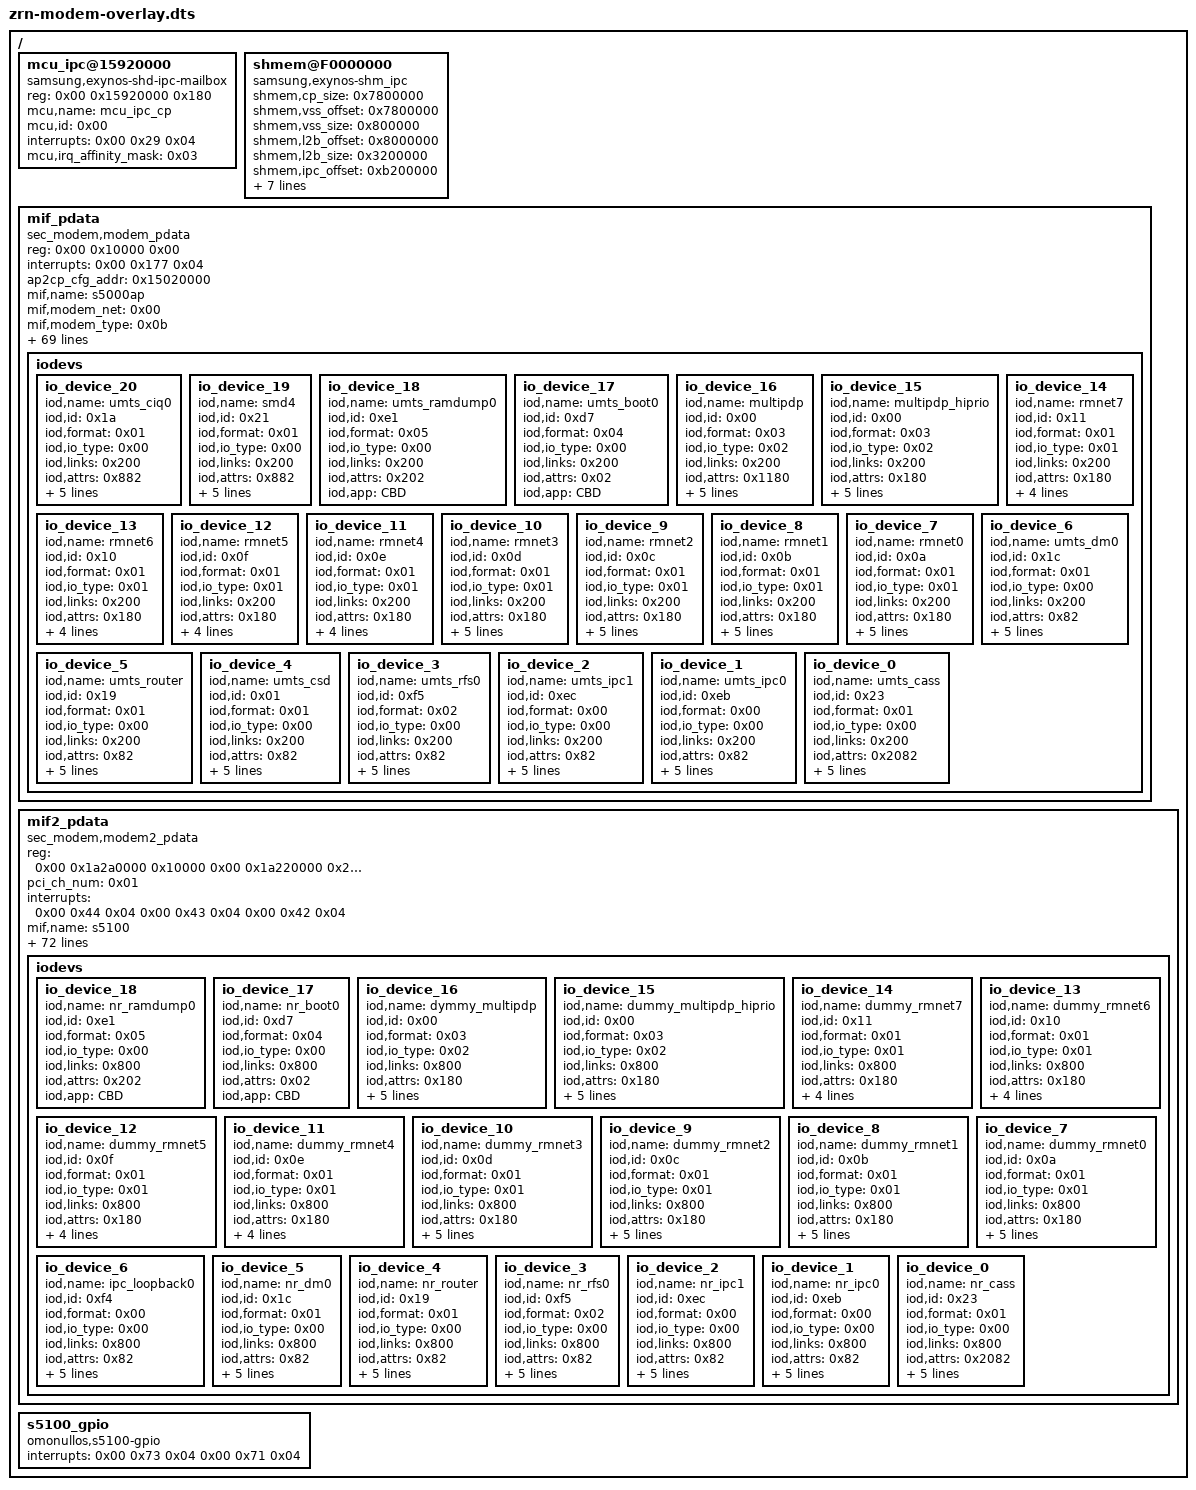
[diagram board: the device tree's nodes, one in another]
/*
 * Generated by modem/beyondx/mkoverlay.py from stock/live/beyondx-twrp-boot.dts:
 * do not edit. See mkoverlay.py for what is dropped and changed.
 */
/dts-v1/;
/plugin/;

/ {
	fragment@0 {
		target-path = "/";
		__overlay__ {
			mcu_ipc@15920000 {
				compatible = "samsung,exynos-shd-ipc-mailbox";
				reg = <0x00 0x15920000 0x180>;
				mcu,name = "mcu_ipc_cp";
				mcu,id = <0x00>;
				interrupts = <0x00 0x29 0x04>;
				mcu,irq_affinity_mask = <0x03>;
			};

			shmem@F0000000 {
				compatible = "samsung,exynos-shm_ipc";
				shmem,cp_size = <0x7800000>;
				shmem,vss_offset = <0x7800000>;
				shmem,vss_size = <0x800000>;
				shmem,l2b_offset = <0x8000000>;
				shmem,l2b_size = <0x3200000>;
				shmem,ipc_offset = <0xb200000>;
				shmem,ipc_size = <0x500000>;
				shmem,zmb_offset = <0x00>;
				shmem,zmb_size = <0x00>;
				shmem,vparam_offset = <0xb700000>;
				shmem,vparam_size = <0x200000>;
				shmem,s5100_ipc_size = <0x800000>;
				shmem,s5100_cp2cp_offset = <0x11600000>;
			};

			mif_pdata {
				reg = <0x00 0x10000 0x00>;
				compatible = "sec_modem,modem_pdata";
				status = "okay";
				interrupts = <0x00 0x177 0x04>;
				ap2cp_cfg_addr = <0x15020000>;
				mif,name = "s5000ap";
				mif,modem_net = <0x00>;
				mif,modem_type = <0x0b>;
				mif,use_handover = <0x00>;
				mif,ipc_version = <0x32>;
				mif,link_types = <0x200>;
				mif,link_name = "shmem";
				mif,link_attrs = <0x7c9>;
				mif,int_ap2cp_msg = <0x00>;
				mif,int_ap2cp_wakeup = <0x01>;
				mif,int_ap2cp_status = <0x02>;
				mif,int_ap2cp_active = <0x03>;
				mif,irq_cp2ap_msg = <0x00>;
				mif,irq_cp2ap_status = <0x02>;
				mif,irq_cp2ap_active = <0x03>;
				mif,irq_cp2ap_perf_req_cpu = <0x05>;
				mif,irq_cp2ap_perf_req_mif = <0x06>;
				mif,irq_cp2ap_perf_req_int = <0x07>;
				mif,irq_cp2ap_wakelock = <0x08>;
				mif,irq_cp2ap_ratmode = <0x09>;
				mif,irq_cp2ap_change_ul_path = <0x0c>;
				mbx_ap2cp_msg = <0x00>;
				mbx_cp2ap_msg = <0x01>;
				mbx_ap2cp_united_status = <0x02>;
				mbx_cp2ap_united_status = <0x03>;
				mbx_cp2ap_dvfsreq_cpu = <0x05>;
				mbx_cp2ap_dvfsreq_mif = <0x06>;
				mbx_cp2ap_dvfsreq_int = <0x07>;
				mbx_ap2cp_kerneltime = <0x09>;
				sbi_nr_crash_type_mask = <0x0f>;
				sbi_nr_crash_type_pos = <0x1b>;
				sbi_crash_type_mask = <0x0f>;
				sbi_crash_type_pos = <0x17>;
				sbi_device_type_mask = <0x1f>;
				sbi_device_type_pos = <0x12>;
				sbi_ext_backtrace_mask = <0x01>;
				sbi_ext_backtrace_pos = <0x11>;
				sbi_ds_det_mask = <0x03>;
				sbi_ds_det_pos = <0x0e>;
				sbi_sys_rev_mask = <0xff>;
				sbi_sys_rev_pos = <0x06>;
				sbi_pda_active_mask = <0x01>;
				sbi_pda_active_pos = <0x05>;
				sbi_ap_status_mask = <0x0f>;
				sbi_ap_status_pos = <0x01>;
				sbi_cp_rat_mode_mask = <0x3f>;
				sbi_cp_rat_mode_pos = <0x1a>;
				sbi_cp_evs_mode_mask = <0x01>;
				sbi_cp_evs_mode_pos = <0x07>;
				sbi_cp2ap_wakelock_mask = <0x01>;
				sbi_cp2ap_wakelock_pos = <0x06>;
				sbi_lte_active_mask = <0x01>;
				sbi_lte_active_pos = <0x05>;
				sbi_cp_status_mask = <0x0f>;
				sbi_cp_status_pos = <0x01>;
				sbi_ap2cp_kerneltime_sec_mask = <0xfff>;
				sbi_ap2cp_kerneltime_sec_pos = <0x14>;
				sbi_ap2cp_kerneltime_usec_mask = <0xfffff>;
				sbi_ap2cp_kerneltime_usec_pos = <0x00>;
				pktproc_support = <0x01>;
				pktproc_version = <0x01>;
				pktproc_cp_base = <0x50000000>;
				pktproc_info_rgn_offset = <0x00>;
				pktproc_info_rgn_size = <0x100>;
				pktproc_desc_rgn_offset = <0x100>;
				pktproc_desc_rgn_size = <0xfff00>;
				pktproc_data_rgn_offset = <0x100000>;
				pktproc_desc_mode = <0x00>;
				pktproc_num_queue = <0x01>;
				pktproc_use_exclusive_irq = <0x00>;
				pktproc_use_hw_iocc = <0x00>;
				mif,num_iodevs = <0x15>;

				iodevs {
					io_device_20 {
						iod,name = "umts_ciq0";
						iod,id = <0x1a>;
						iod,format = <0x01>;
						iod,io_type = <0x00>;
						iod,links = <0x200>;
						iod,attrs = <0x882>;
						iod,ul_num_buffers = <0x10>;
						iod,ul_buffer_size = <0x800>;
						iod,dl_num_buffers = <0x80>;
						iod,dl_buffer_size = <0x800>;
						iod,option_region = "usa_spr";
					};

					io_device_19 {
						iod,name = "smd4";
						iod,id = <0x21>;
						iod,format = <0x01>;
						iod,io_type = <0x00>;
						iod,links = <0x200>;
						iod,attrs = <0x882>;
						iod,ul_num_buffers = <0x10>;
						iod,ul_buffer_size = <0x800>;
						iod,dl_num_buffers = <0x80>;
						iod,dl_buffer_size = <0x800>;
						iod,option_region = "kor_skt";
					};

					io_device_18 {
						iod,name = "umts_ramdump0";
						iod,id = <0xe1>;
						iod,format = <0x05>;
						iod,io_type = <0x00>;
						iod,links = <0x200>;
						iod,attrs = <0x202>;
						iod,app = "CBD";
					};

					io_device_17 {
						iod,name = "umts_boot0";
						iod,id = <0xd7>;
						iod,format = <0x04>;
						iod,io_type = <0x00>;
						iod,links = <0x200>;
						iod,attrs = <0x02>;
						iod,app = "CBD";
					};

					io_device_16 {
						iod,name = "multipdp";
						iod,id = <0x00>;
						iod,format = <0x03>;
						iod,io_type = <0x02>;
						iod,links = <0x200>;
						iod,attrs = <0x1180>;
						iod,app = "RIL";
						iod,ul_num_buffers = <0x200>;
						iod,ul_buffer_size = <0x800>;
						iod,dl_num_buffers = <0x400>;
						iod,dl_buffer_size = <0x08>;
					};

					io_device_15 {
						iod,name = "multipdp_hiprio";
						iod,id = <0x00>;
						iod,format = <0x03>;
						iod,io_type = <0x02>;
						iod,links = <0x200>;
						iod,attrs = <0x180>;
						iod,app = "RIL";
						iod,ul_num_buffers = <0x100>;
						iod,ul_buffer_size = <0x800>;
						iod,dl_num_buffers = <0x100>;
						iod,dl_buffer_size = <0x800>;
					};

					io_device_14 {
						iod,name = "rmnet7";
						iod,id = <0x11>;
						iod,format = <0x01>;
						iod,io_type = <0x01>;
						iod,links = <0x200>;
						iod,attrs = <0x180>;
						iod,ul_num_buffers = <0x00>;
						iod,ul_buffer_size = <0x800>;
						iod,dl_num_buffers = <0x00>;
						iod,dl_buffer_size = <0x800>;
					};

					io_device_13 {
						iod,name = "rmnet6";
						iod,id = <0x10>;
						iod,format = <0x01>;
						iod,io_type = <0x01>;
						iod,links = <0x200>;
						iod,attrs = <0x180>;
						iod,ul_num_buffers = <0x00>;
						iod,ul_buffer_size = <0x800>;
						iod,dl_num_buffers = <0x00>;
						iod,dl_buffer_size = <0x800>;
					};

					io_device_12 {
						iod,name = "rmnet5";
						iod,id = <0x0f>;
						iod,format = <0x01>;
						iod,io_type = <0x01>;
						iod,links = <0x200>;
						iod,attrs = <0x180>;
						iod,ul_num_buffers = <0x00>;
						iod,ul_buffer_size = <0x800>;
						iod,dl_num_buffers = <0x00>;
						iod,dl_buffer_size = <0x800>;
					};

					io_device_11 {
						iod,name = "rmnet4";
						iod,id = <0x0e>;
						iod,format = <0x01>;
						iod,io_type = <0x01>;
						iod,links = <0x200>;
						iod,attrs = <0x180>;
						iod,ul_num_buffers = <0x00>;
						iod,ul_buffer_size = <0x800>;
						iod,dl_num_buffers = <0x00>;
						iod,dl_buffer_size = <0x800>;
					};

					io_device_10 {
						iod,name = "rmnet3";
						iod,id = <0x0d>;
						iod,format = <0x01>;
						iod,io_type = <0x01>;
						iod,links = <0x200>;
						iod,attrs = <0x180>;
						iod,app = "NET";
						iod,ul_num_buffers = <0x00>;
						iod,ul_buffer_size = <0x800>;
						iod,dl_num_buffers = <0x00>;
						iod,dl_buffer_size = <0x800>;
					};

					io_device_9 {
						iod,name = "rmnet2";
						iod,id = <0x0c>;
						iod,format = <0x01>;
						iod,io_type = <0x01>;
						iod,links = <0x200>;
						iod,attrs = <0x180>;
						iod,app = "NET";
						iod,ul_num_buffers = <0x00>;
						iod,ul_buffer_size = <0x800>;
						iod,dl_num_buffers = <0x00>;
						iod,dl_buffer_size = <0x800>;
					};

					io_device_8 {
						iod,name = "rmnet1";
						iod,id = <0x0b>;
						iod,format = <0x01>;
						iod,io_type = <0x01>;
						iod,links = <0x200>;
						iod,attrs = <0x180>;
						iod,app = "NET";
						iod,ul_num_buffers = <0x00>;
						iod,ul_buffer_size = <0x800>;
						iod,dl_num_buffers = <0x00>;
						iod,dl_buffer_size = <0x800>;
					};

					io_device_7 {
						iod,name = "rmnet0";
						iod,id = <0x0a>;
						iod,format = <0x01>;
						iod,io_type = <0x01>;
						iod,links = <0x200>;
						iod,attrs = <0x180>;
						iod,app = "NET";
						iod,ul_num_buffers = <0x00>;
						iod,ul_buffer_size = <0x800>;
						iod,dl_num_buffers = <0x00>;
						iod,dl_buffer_size = <0x800>;
					};

					io_device_6 {
						iod,name = "umts_dm0";
						iod,id = <0x1c>;
						iod,format = <0x01>;
						iod,io_type = <0x00>;
						iod,links = <0x200>;
						iod,attrs = <0x82>;
						iod,app = "DIAG";
						iod,ul_num_buffers = <0x10>;
						iod,ul_buffer_size = <0x800>;
						iod,dl_num_buffers = <0x80>;
						iod,dl_buffer_size = <0x800>;
					};

					io_device_5 {
						iod,name = "umts_router";
						iod,id = <0x19>;
						iod,format = <0x01>;
						iod,io_type = <0x00>;
						iod,links = <0x200>;
						iod,attrs = <0x82>;
						iod,app = "Data Router";
						iod,ul_num_buffers = <0x10>;
						iod,ul_buffer_size = <0x800>;
						iod,dl_num_buffers = <0x10>;
						iod,dl_buffer_size = <0x800>;
					};

					io_device_4 {
						iod,name = "umts_csd";
						iod,id = <0x01>;
						iod,format = <0x01>;
						iod,io_type = <0x00>;
						iod,links = <0x200>;
						iod,attrs = <0x82>;
						iod,app = "CSVT";
						iod,ul_num_buffers = <0x20>;
						iod,ul_buffer_size = <0x800>;
						iod,dl_num_buffers = <0x40>;
						iod,dl_buffer_size = <0x800>;
					};

					io_device_3 {
						iod,name = "umts_rfs0";
						iod,id = <0xf5>;
						iod,format = <0x02>;
						iod,io_type = <0x00>;
						iod,links = <0x200>;
						iod,attrs = <0x82>;
						iod,app = "RFS";
						iod,ul_num_buffers = <0x10>;
						iod,ul_buffer_size = <0x800>;
						iod,dl_num_buffers = <0x200>;
						iod,dl_buffer_size = <0x800>;
					};

					io_device_2 {
						iod,name = "umts_ipc1";
						iod,id = <0xec>;
						iod,format = <0x00>;
						iod,io_type = <0x00>;
						iod,links = <0x200>;
						iod,attrs = <0x82>;
						iod,app = "RIL";
						iod,ul_num_buffers = <0x10>;
						iod,ul_buffer_size = <0x1000>;
						iod,dl_num_buffers = <0x20>;
						iod,dl_buffer_size = <0x1000>;
					};

					io_device_1 {
						iod,name = "umts_ipc0";
						iod,id = <0xeb>;
						iod,format = <0x00>;
						iod,io_type = <0x00>;
						iod,links = <0x200>;
						iod,attrs = <0x82>;
						iod,app = "RIL";
						iod,ul_num_buffers = <0x10>;
						iod,ul_buffer_size = <0x1000>;
						iod,dl_num_buffers = <0x20>;
						iod,dl_buffer_size = <0x1000>;
					};

					io_device_0 {
						iod,name = "umts_cass";
						iod,id = <0x23>;
						iod,format = <0x01>;
						iod,io_type = <0x00>;
						iod,links = <0x200>;
						iod,attrs = <0x2082>;
						iod,max_tx_size = <0x800>;
						iod,ul_num_buffers = <0x10>;
						iod,ul_buffer_size = <0x800>;
						iod,dl_num_buffers = <0x10>;
						iod,dl_buffer_size = <0x800>;
					};
				};
			};

			mif2_pdata {
				reg = <0x00 0x1a2a0000 0x10000 0x00 0x1a220000 0x2000>;
				reg-names = "dit\0sysreg_busc";
				compatible = "sec_modem,modem2_pdata";
				status = "okay";
				pci_ch_num = <0x01>;
				interrupts = <0x00 0x44 0x04 0x00 0x43 0x04 0x00 0x42 0x04>;
				interrupt-names = "DIT_BUS_ERR\0DIT_RX\0DIT_TX";
				mif,name = "s5100";
				mif,modem_net = <0x00>;
				mif,modem_type = <0x0c>;
				mif,use_handover = <0x00>;
				mif,ipc_version = <0x32>;
				mif,link_types = <0x800>;
				mif,link_name = "PCIE";
				mif,link_attrs = <0x7c9>;
				mif,int_ap2cp_msg = <0x00>;
				mif,int_ap2cp_wakeup = <0x01>;
				mif,int_ap2cp_status = <0x02>;
				mif,int_ap2cp_active = <0x03>;
				mif,int_ap2cp_pcie_link_ack = <0x0e>;
				mif,irq_cp2ap_msg = <0x00>;
				mif,irq_cp2ap_status = <0x02>;
				mif,irq_cp2ap_active = <0x03>;
				mif,irq_cp2ap_perf_req_cpu = <0x05>;
				mif,irq_cp2ap_perf_req_mif = <0x06>;
				mif,irq_cp2ap_perf_req_int = <0x07>;
				mif,irq_cp2ap_wakelock = <0x08>;
				mif,irq_cp2ap_ratmode = <0x09>;
				mif,irq_cp2ap_change_ul_path = <0x0c>;
				mbx_ap2cp_msg = <0x00>;
				mbx_cp2ap_msg = <0x01>;
				mbx_ap2cp_united_status = <0x02>;
				mbx_cp2ap_united_status = <0x03>;
				mbx_cp2ap_dvfsreq_cpu = <0x05>;
				mbx_cp2ap_dvfsreq_mif = <0x06>;
				mbx_cp2ap_dvfsreq_int = <0x07>;
				mbx_ap2cp_kerneltime = <0x09>;
				sbi_crash_type_mask = <0x0f>;
				sbi_crash_type_pos = <0x17>;
				sbi_ext_backtrace_mask = <0x01>;
				sbi_ext_backtrace_pos = <0x11>;
				sbi_ds_det_mask = <0x03>;
				sbi_ds_det_pos = <0x0e>;
				sbi_sys_rev_mask = <0xff>;
				sbi_sys_rev_pos = <0x06>;
				sbi_pda_active_mask = <0x01>;
				sbi_pda_active_pos = <0x05>;
				sbi_ap_status_mask = <0x0f>;
				sbi_ap_status_pos = <0x01>;
				sbi_cp_rat_mode_mask = <0x3f>;
				sbi_cp_rat_mode_pos = <0x1a>;
				sbi_cp_evs_mode_mask = <0x01>;
				sbi_cp_evs_mode_pos = <0x07>;
				sbi_cp2ap_wakelock_mask = <0x01>;
				sbi_cp2ap_wakelock_pos = <0x06>;
				sbi_lte_active_mask = <0x01>;
				sbi_lte_active_pos = <0x05>;
				sbi_cp_status_mask = <0x0f>;
				sbi_cp_status_pos = <0x01>;
				sbi_ap2cp_kerneltime_sec_mask = <0xfff>;
				sbi_ap2cp_kerneltime_sec_pos = <0x14>;
				sbi_ap2cp_kerneltime_usec_mask = <0xfffff>;
				sbi_ap2cp_kerneltime_usec_pos = <0x00>;
				dit_support = <0x01>;
				dit_version = <0x01>;
				dit_num_desc_rx = <0x2000>;
				dit_irq_affinity_rx = <0x02>;
				pktproc_support = <0x01>;
				pktproc_version = <0x02>;
				pktproc_cp_base = <0x30800000>;
				pktproc_info_rgn_offset = <0x00>;
				pktproc_info_rgn_size = <0x100>;
				pktproc_desc_rgn_offset = <0x100>;
				pktproc_desc_rgn_size = <0xfff00>;
				pktproc_data_rgn_offset = <0x100000>;
				pktproc_desc_mode = <0x00>;
				pktproc_num_queue = <0x01>;
				pktproc_use_exclusive_irq = <0x00>;
				pktproc_use_hw_iocc = <0x01>;
				mif,num_iodevs = <0x13>;

				iodevs {
					io_device_18 {
						iod,name = "nr_ramdump0";
						iod,id = <0xe1>;
						iod,format = <0x05>;
						iod,io_type = <0x00>;
						iod,links = <0x800>;
						iod,attrs = <0x202>;
						iod,app = "CBD";
					};

					io_device_17 {
						iod,name = "nr_boot0";
						iod,id = <0xd7>;
						iod,format = <0x04>;
						iod,io_type = <0x00>;
						iod,links = <0x800>;
						iod,attrs = <0x02>;
						iod,app = "CBD";
					};

					io_device_16 {
						iod,name = "dymmy_multipdp";
						iod,id = <0x00>;
						iod,format = <0x03>;
						iod,io_type = <0x02>;
						iod,links = <0x800>;
						iod,attrs = <0x180>;
						iod,app = "RIL";
						iod,ul_num_buffers = <0x200>;
						iod,ul_buffer_size = <0x800>;
						iod,dl_num_buffers = <0x400>;
						iod,dl_buffer_size = <0x800>;
					};

					io_device_15 {
						iod,name = "dummy_multipdp_hiprio";
						iod,id = <0x00>;
						iod,format = <0x03>;
						iod,io_type = <0x02>;
						iod,links = <0x800>;
						iod,attrs = <0x180>;
						iod,app = "RIL";
						iod,ul_num_buffers = <0x100>;
						iod,ul_buffer_size = <0x800>;
						iod,dl_num_buffers = <0x100>;
						iod,dl_buffer_size = <0x800>;
					};

					io_device_14 {
						iod,name = "dummy_rmnet7";
						iod,id = <0x11>;
						iod,format = <0x01>;
						iod,io_type = <0x01>;
						iod,links = <0x800>;
						iod,attrs = <0x180>;
						iod,ul_num_buffers = <0x00>;
						iod,ul_buffer_size = <0x800>;
						iod,dl_num_buffers = <0x00>;
						iod,dl_buffer_size = <0x800>;
					};

					io_device_13 {
						iod,name = "dummy_rmnet6";
						iod,id = <0x10>;
						iod,format = <0x01>;
						iod,io_type = <0x01>;
						iod,links = <0x800>;
						iod,attrs = <0x180>;
						iod,ul_num_buffers = <0x00>;
						iod,ul_buffer_size = <0x800>;
						iod,dl_num_buffers = <0x00>;
						iod,dl_buffer_size = <0x800>;
					};

					io_device_12 {
						iod,name = "dummy_rmnet5";
						iod,id = <0x0f>;
						iod,format = <0x01>;
						iod,io_type = <0x01>;
						iod,links = <0x800>;
						iod,attrs = <0x180>;
						iod,ul_num_buffers = <0x00>;
						iod,ul_buffer_size = <0x800>;
						iod,dl_num_buffers = <0x00>;
						iod,dl_buffer_size = <0x800>;
					};

					io_device_11 {
						iod,name = "dummy_rmnet4";
						iod,id = <0x0e>;
						iod,format = <0x01>;
						iod,io_type = <0x01>;
						iod,links = <0x800>;
						iod,attrs = <0x180>;
						iod,ul_num_buffers = <0x00>;
						iod,ul_buffer_size = <0x800>;
						iod,dl_num_buffers = <0x00>;
						iod,dl_buffer_size = <0x800>;
					};

					io_device_10 {
						iod,name = "dummy_rmnet3";
						iod,id = <0x0d>;
						iod,format = <0x01>;
						iod,io_type = <0x01>;
						iod,links = <0x800>;
						iod,attrs = <0x180>;
						iod,app = "NET";
						iod,ul_num_buffers = <0x00>;
						iod,ul_buffer_size = <0x800>;
						iod,dl_num_buffers = <0x00>;
						iod,dl_buffer_size = <0x800>;
					};

					io_device_9 {
						iod,name = "dummy_rmnet2";
						iod,id = <0x0c>;
						iod,format = <0x01>;
						iod,io_type = <0x01>;
						iod,links = <0x800>;
						iod,attrs = <0x180>;
						iod,app = "NET";
						iod,ul_num_buffers = <0x00>;
						iod,ul_buffer_size = <0x800>;
						iod,dl_num_buffers = <0x00>;
						iod,dl_buffer_size = <0x800>;
					};

					io_device_8 {
						iod,name = "dummy_rmnet1";
						iod,id = <0x0b>;
						iod,format = <0x01>;
						iod,io_type = <0x01>;
						iod,links = <0x800>;
						iod,attrs = <0x180>;
						iod,app = "NET";
						iod,ul_num_buffers = <0x00>;
						iod,ul_buffer_size = <0x800>;
						iod,dl_num_buffers = <0x00>;
						iod,dl_buffer_size = <0x800>;
					};

					io_device_7 {
						iod,name = "dummy_rmnet0";
						iod,id = <0x0a>;
						iod,format = <0x01>;
						iod,io_type = <0x01>;
						iod,links = <0x800>;
						iod,attrs = <0x180>;
						iod,app = "NET";
						iod,ul_num_buffers = <0x00>;
						iod,ul_buffer_size = <0x800>;
						iod,dl_num_buffers = <0x00>;
						iod,dl_buffer_size = <0x800>;
					};

					io_device_6 {
						iod,name = "ipc_loopback0";
						iod,id = <0xf4>;
						iod,format = <0x00>;
						iod,io_type = <0x00>;
						iod,links = <0x800>;
						iod,attrs = <0x82>;
						iod,app = "CLD";
						iod,ul_num_buffers = <0x10>;
						iod,ul_buffer_size = <0x800>;
						iod,dl_num_buffers = <0x20>;
						iod,dl_buffer_size = <0x800>;
					};

					io_device_5 {
						iod,name = "nr_dm0";
						iod,id = <0x1c>;
						iod,format = <0x01>;
						iod,io_type = <0x00>;
						iod,links = <0x800>;
						iod,attrs = <0x82>;
						iod,app = "DIAG";
						iod,ul_num_buffers = <0x10>;
						iod,ul_buffer_size = <0x800>;
						iod,dl_num_buffers = <0x80>;
						iod,dl_buffer_size = <0x800>;
					};

					io_device_4 {
						iod,name = "nr_router";
						iod,id = <0x19>;
						iod,format = <0x01>;
						iod,io_type = <0x00>;
						iod,links = <0x800>;
						iod,attrs = <0x82>;
						iod,app = "Data Router";
						iod,ul_num_buffers = <0x10>;
						iod,ul_buffer_size = <0x800>;
						iod,dl_num_buffers = <0x10>;
						iod,dl_buffer_size = <0x800>;
					};

					io_device_3 {
						iod,name = "nr_rfs0";
						iod,id = <0xf5>;
						iod,format = <0x02>;
						iod,io_type = <0x00>;
						iod,links = <0x800>;
						iod,attrs = <0x82>;
						iod,app = "RFS";
						iod,ul_num_buffers = <0x10>;
						iod,ul_buffer_size = <0x800>;
						iod,dl_num_buffers = <0x200>;
						iod,dl_buffer_size = <0x800>;
					};

					io_device_2 {
						iod,name = "nr_ipc1";
						iod,id = <0xec>;
						iod,format = <0x00>;
						iod,io_type = <0x00>;
						iod,links = <0x800>;
						iod,attrs = <0x82>;
						iod,app = "RIL";
						iod,ul_num_buffers = <0x10>;
						iod,ul_buffer_size = <0x1000>;
						iod,dl_num_buffers = <0x20>;
						iod,dl_buffer_size = <0x1000>;
					};

					io_device_1 {
						iod,name = "nr_ipc0";
						iod,id = <0xeb>;
						iod,format = <0x00>;
						iod,io_type = <0x00>;
						iod,links = <0x800>;
						iod,attrs = <0x82>;
						iod,app = "RIL";
						iod,ul_num_buffers = <0x10>;
						iod,ul_buffer_size = <0x1000>;
						iod,dl_num_buffers = <0x20>;
						iod,dl_buffer_size = <0x1000>;
					};

					io_device_0 {
						iod,name = "nr_cass";
						iod,id = <0x23>;
						iod,format = <0x01>;
						iod,io_type = <0x00>;
						iod,links = <0x800>;
						iod,attrs = <0x2082>;
						iod,max_tx_size = <0x800>;
						iod,ul_num_buffers = <0x10>;
						iod,ul_buffer_size = <0x800>;
						iod,dl_num_buffers = <0x10>;
						iod,dl_buffer_size = <0x800>;
					};
				};
			};

			s5100_gpio {
				compatible = "omonullos,s5100-gpio";
				interrupts = <0x00 0x73 0x04 0x00 0x71 0x04>;	/* gpm30, gpm28 */
			};
		};
	};
};
